# STM32L062 register map
File version: 1.2
CPU: CM0+ r0p0, little endian, MPU, no FPU, 4 interrupt priority bits
Registers are 32-bit, read-write, reset 0x0 unless marked. A register's access mark holds for its fields unless they carry their own. Offsets are from the block's base; [hi:lo] are bit positions.

## SPI1 — Serial peripheral interface
Base 0x40013000
Same registers: SPI2 0x40003800
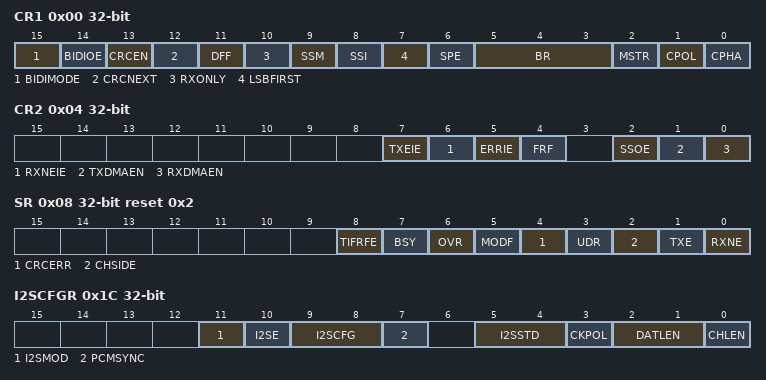
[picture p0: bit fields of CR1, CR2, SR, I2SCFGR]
0x00 CR1 — control register 1
  [15] BIDIMODE — Bidirectional data mode enable
  [14] BIDIOE — Output enable in bidirectional mode
  [13] CRCEN — Hardware CRC calculation enable
  [12] CRCNEXT — CRC transfer next
  [11] DFF — Data frame format
  [10] RXONLY — Receive only
  [9] SSM — Software slave management
  [8] SSI — Internal slave select
  [7] LSBFIRST — Frame format
  [6] SPE — SPI enable
  [5:3] BR — Baud rate control
  [2] MSTR — Master selection
  [1] CPOL — Clock polarity
  [0] CPHA — Clock phase
0x04 CR2 — control register 2
  [7] TXEIE — Tx buffer empty interrupt enable
  [6] RXNEIE — RX buffer not empty interrupt enable
  [5] ERRIE — Error interrupt enable
  [4] FRF — Frame format
  [2] SSOE — SS output enable
  [1] TXDMAEN — Tx buffer DMA enable
  [0] RXDMAEN — Rx buffer DMA enable
0x08 SR access per field reset 0x2 — status register
  [8] TIFRFE ro — TI frame format error
  [7] BSY ro — Busy flag
  [6] OVR ro — Overrun flag
  [5] MODF ro — Mode fault
  [4] CRCERR rw — CRC error flag
  [3] UDR ro — Underrun flag
  [2] CHSIDE ro — Channel side
  [1] TXE ro — Transmit buffer empty
  [0] RXNE ro — Receive buffer not empty
0x0C DR — data register
  [15:0] DR — Data register
0x10 CRCPR reset 0x7 — CRC polynomial register
  [15:0] CRCPOLY
0x14 RXCRCR ro — RX CRC register
  [15:0] RxCRC
0x18 TXCRCR ro — TX CRC register
  [15:0] TxCRC
0x1C I2SCFGR — I2S configuration register
  [11] I2SMOD — I2S mode selection
  [10] I2SE — I2S Enable
  [9:8] I2SCFG — I2S configuration mode
  [7] PCMSYNC — PCM frame synchronization
  [5:4] I2SSTD — I2S standard selection
  [3] CKPOL — Steady state clock polarity
  [2:1] DATLEN — Data length to be transferred
  [0] CHLEN — Channel length (number of bits per audio channel)
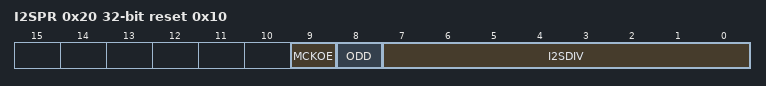
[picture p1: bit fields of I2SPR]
0x20 I2SPR reset 0x10 — I2S prescaler register
  [9] MCKOE — Master clock output enable
  [8] ODD — Odd factor for the prescaler
  [7:0] I2SDIV — I2S Linear prescaler

## PWR — Power control
Base 0x40007000
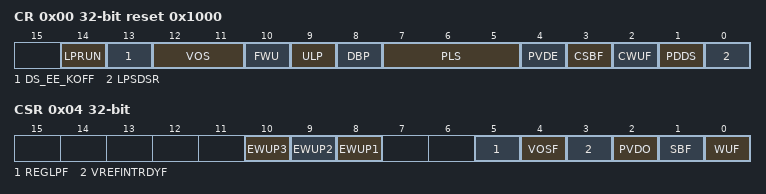
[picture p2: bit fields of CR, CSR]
0x00 CR reset 0x1000 — power control register
  [14] LPRUN — Low power run mode
  [13] DS_EE_KOFF — Deep sleep mode with Flash memory kept off
  [12:11] VOS — Voltage scaling range selection
  [10] FWU — Fast wakeup
  [9] ULP — Ultra-low-power mode
  [8] DBP — Disable backup domain write protection
  [7:5] PLS — PVD level selection
  [4] PVDE — Power voltage detector enable
  [3] CSBF — Clear standby flag
  [2] CWUF — Clear wakeup flag
  [1] PDDS — Power down deepsleep
  [0] LPSDSR — Low-power deepsleep/Sleep/Low-power run
0x04 CSR access per field — power control/status register
  [10] EWUP3 rw — Enable WKUP pin 3
  [9] EWUP2 rw — Enable WKUP pin 2
  [8] EWUP1 rw — Enable WKUP pin 1
  [5] REGLPF ro — Regulator LP flag
  [4] VOSF ro — Voltage Scaling select flag
  [3] VREFINTRDYF ro — Internal voltage reference (VREFINT) ready flag This bit indicates the state of the internal voltage reference, VREFINT.
  [2] PVDO ro — PVD output
  [1] SBF ro — Standby flag
  [0] WUF ro — Wakeup flag

## Flash
Base 0x40022000
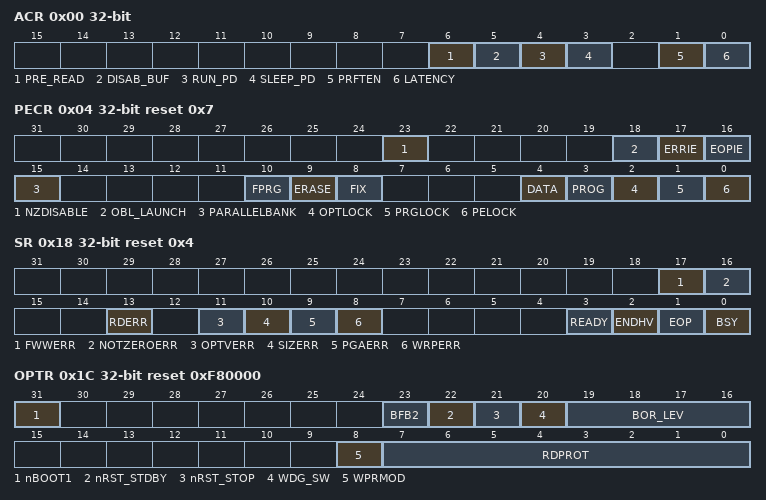
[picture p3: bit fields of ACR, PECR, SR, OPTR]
0x00 ACR — Access control register
  [6] PRE_READ — Pre-read data address
  [5] DISAB_BUF — Disable Buffer
  [4] RUN_PD — Flash mode during Run
  [3] SLEEP_PD — Flash mode during Sleep
  [1] PRFTEN — Prefetch enable
  [0] LATENCY
0x04 PECR reset 0x7 — Program/erase control register
  [23] NZDISABLE — Non-Zero check notification disable
  [18] OBL_LAUNCH — Launch the option byte loading
  [17] ERRIE — Error interrupt enable
  [16] EOPIE — End of programming interrupt enable
  [15] PARALLELBANK — Parallel bank mode
  [10] FPRG — Half Page/Double Word programming mode
  [9] ERASE — Page or Double Word erase mode
  [8] FIX — Fixed time data write for Byte, Half Word and Word programming
  [4] DATA — Data EEPROM selection
  [3] PROG — Program memory selection
  [2] OPTLOCK — Option bytes block lock
  [1] PRGLOCK — Program memory lock
  [0] PELOCK — FLASH_PECR and data EEPROM lock
0x08 PDKEYR wo — Power down key register
  [31:0] PDKEYR — RUN_PD in FLASH_ACR key
0x0C PEKEYR wo — Program/erase key register
  [31:0] PEKEYR — FLASH_PEC and data EEPROM key
0x10 PRGKEYR wo — Program memory key register
  [31:0] PRGKEYR — Program memory key
0x14 OPTKEYR wo — Option byte key register
  [31:0] OPTKEYR — Option byte key
0x18 SR access per field reset 0x4 — Status register
  [17] FWWERR rw
  [16] NOTZEROERR rw
  [13] RDERR rw
  [11] OPTVERR rw — Option validity error
  [10] SIZERR rw — Size error
  [9] PGAERR rw — Programming alignment error
  [8] WRPERR rw — Write protected error
  [3] READY ro — Flash memory module ready after low power mode
  [2] ENDHV ro — End of high voltage
  [1] EOP ro — End of operation
  [0] BSY ro — Write/erase operations in progress
0x1C OPTR ro reset 0xF80000 — Option byte register
  [31] nBOOT1
  [23] BFB2
  [22] nRST_STDBY
  [21] nRST_STOP
  [20] WDG_SW
  [19:16] BOR_LEV
  [8] WPRMOD
  [7:0] RDPROT — Read protection
0x20 WRPROT1 ro — Write protection register
  [31:0] WRPROT1 — Write protection
0x80 WRPROT2 ro — Write protection register
  [15:0] WRPROT2 — Write protection
